# CY8C5888LTI_LP097 register map
File version: 0.1
Registers are 8-bit, read-write, no defined reset value unless marked. A register's access mark holds for its fields unless they carry their own. Offsets are from the block's base; [hi:lo] are bit positions; 'fields as' and 'values as' point back to an identical list.

## PIXY2UARTReset
Base 0x00000000
0x40006478 PIXY2UARTReset_CONTROL_REG

## PIXY2PacketCount
Base 0x00000000
0x4000640D PIXY2PacketCount_COUNTER — UDB.A0 - Current Counter Value
0x4000642D PIXY2PacketCount_PERIOD — UDB.D0 - Assigned Period
0x4000643D PIXY2PacketCount_COMPARE — UDB.D1 - Assigned Compare Value
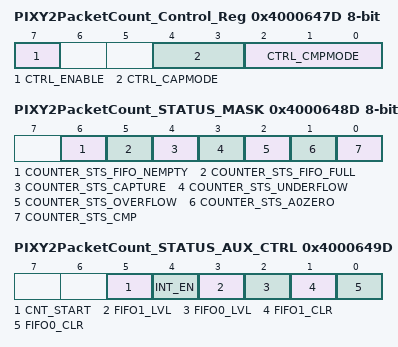
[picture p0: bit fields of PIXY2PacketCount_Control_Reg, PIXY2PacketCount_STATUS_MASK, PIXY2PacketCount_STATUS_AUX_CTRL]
0x4000647D PIXY2PacketCount_Control_Reg — UDB Control Register - Assigned Control Register Value
  [7] CTRL_ENABLE — Enable Counter
  [4:3] CTRL_CAPMODE — Capture mode
  [2:0] CTRL_CMPMODE — Compare mode
0x4000648D PIXY2PacketCount_STATUS_MASK — UDB Status bits Interrupt Mask Enable Register
  [6] COUNTER_STS_FIFO_NEMPTY — FIFO Not Empty Status
  [5] COUNTER_STS_FIFO_FULL — FIFO Full Status
  [4] COUNTER_STS_CAPTURE — Capture Status
  [3] COUNTER_STS_UNDERFLOW — Underflow status
  [2] COUNTER_STS_OVERFLOW — Overflow status
  [1] COUNTER_STS_A0ZERO — A0 Zero ouput status
  [0] COUNTER_STS_CMP — Compare output status
0x4000649D PIXY2PacketCount_STATUS_AUX_CTRL — UDB Auxilliary Control Register
  [5] CNT_START — FIFO0 clear
    0=E_CNT_START0 (Disable counter); 1=E_CNT_START1 (Enable counter)
  [4] INT_EN
    0=E_INT_EN0 (Interrupt disabled); 1=E_INT_EN1 (Interrupt enabled)
  [3] FIFO1_LVL — FIFO level
    0=E_FIFO_LVL_0 (FIFO LVL: input mode: FIFO not full; output mode: FIFO not empty); 1=E_FIFO_LVL_1 (FIFO LVL: input mode: FIFO at least 1/2 empty; output mode: FIFO at least 1/2 full)
  [2] FIFO0_LVL — FIFO level
    values as FIFO1_LVL
  [1] FIFO1_CLR — FIFO1 clear
    0=E_FIFO_CLR_0 (Normal FIFO operation); 1=E_FIFO_CLR_1 (Clear FIFO state)
  [0] FIFO0_CLR — FIFO0 clear
    values as FIFO1_CLR

## PIXYCountReset
Base 0x00000000
0x4000647E PIXYCountReset_CONTROL_REG

## UARTReset
Base 0x00000000
0x4000657B UARTReset_CONTROL_REG

## LEDDrive
Base 0x00000000
0x4000647C LEDDrive_CONTROL_REG

## LabVIEW_UART — UART
Base 0x00000000
0x4000644E TX_LabVIEW_UART_TX_DATA — TX Data Register
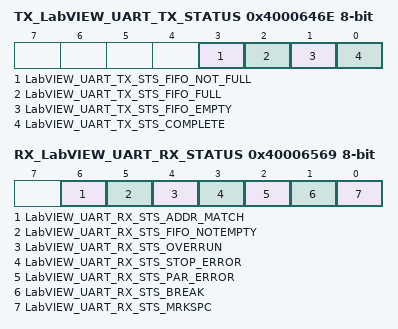
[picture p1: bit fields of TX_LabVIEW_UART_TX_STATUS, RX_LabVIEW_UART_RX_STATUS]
0x4000646E TX_LabVIEW_UART_TX_STATUS — TX status register
  [3] LabVIEW_UART_TX_STS_FIFO_NOT_FULL ro, [2] LabVIEW_UART_TX_STS_FIFO_FULL ro, [1] LabVIEW_UART_TX_STS_FIFO_EMPTY ro, [0] LabVIEW_UART_TX_STS_COMPLETE ro
0x4000652B RX_LabVIEW_UART_RX_ADDRESS1 — RX Address1 Register
0x4000653B RX_LabVIEW_UART_RX_ADDRESS2 — RX Address2 Register
0x4000654B RX_LabVIEW_UART_RX_DATA — RX Data Register
0x40006569 RX_LabVIEW_UART_RX_STATUS — RX status register
  [6] LabVIEW_UART_RX_STS_ADDR_MATCH ro, [5] LabVIEW_UART_RX_STS_FIFO_NOTEMPTY ro, [4] LabVIEW_UART_RX_STS_OVERRUN ro, [3] LabVIEW_UART_RX_STS_STOP_ERROR ro, [2] LabVIEW_UART_RX_STS_PAR_ERROR ro, [1] LabVIEW_UART_RX_STS_BREAK ro, [0] LabVIEW_UART_RX_STS_MRKSPC ro

## ByteCountReset
Base 0x00000000
0x40006579 ByteCountReset_CONTROL_REG

## PIXY2UART — UART
Base 0x00000000
0x40006428 RX_PIXY2UART_RX_ADDRESS1 — RX Address1 Register
0x40006438 RX_PIXY2UART_RX_ADDRESS2 — RX Address2 Register
0x40006448 RX_PIXY2UART_RX_DATA — RX Data Register
0x4000644C TX_PIXY2UART_TX_DATA — TX Data Register
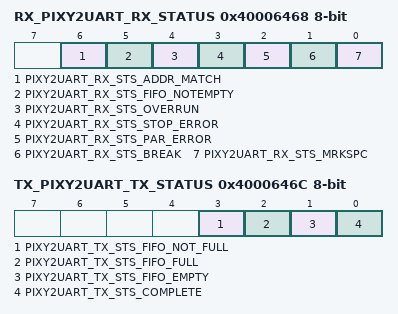
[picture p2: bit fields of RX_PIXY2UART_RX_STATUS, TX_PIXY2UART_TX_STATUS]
0x40006468 RX_PIXY2UART_RX_STATUS — RX status register
  [6] PIXY2UART_RX_STS_ADDR_MATCH ro, [5] PIXY2UART_RX_STS_FIFO_NOTEMPTY ro, [4] PIXY2UART_RX_STS_OVERRUN ro, [3] PIXY2UART_RX_STS_STOP_ERROR ro, [2] PIXY2UART_RX_STS_PAR_ERROR ro, [1] PIXY2UART_RX_STS_BREAK ro, [0] PIXY2UART_RX_STS_MRKSPC ro
0x4000646C TX_PIXY2UART_TX_STATUS — TX status register
  [3] PIXY2UART_TX_STS_FIFO_NOT_FULL ro, [2] PIXY2UART_TX_STS_FIFO_FULL ro, [1] PIXY2UART_TX_STS_FIFO_EMPTY ro, [0] PIXY2UART_TX_STS_COMPLETE ro

## ByteCounter
Base 0x00000000
0x40006409 ByteCounter_COUNTER — UDB.A0 - Current Counter Value
0x40006429 ByteCounter_PERIOD — UDB.D0 - Assigned Period
0x40006439 ByteCounter_COMPARE — UDB.D1 - Assigned Compare Value
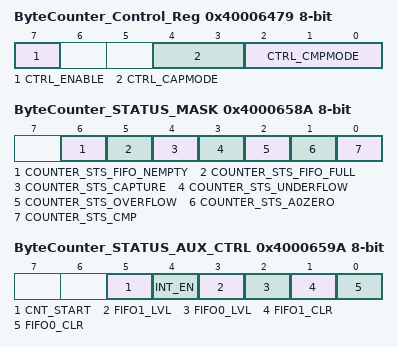
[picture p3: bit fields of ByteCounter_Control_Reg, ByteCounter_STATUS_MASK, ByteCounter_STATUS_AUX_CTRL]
0x40006479 ByteCounter_Control_Reg — UDB Control Register - Assigned Control Register Value
  [7] CTRL_ENABLE — Enable Counter
  [4:3] CTRL_CAPMODE — Capture mode
  [2:0] CTRL_CMPMODE — Compare mode
0x4000658A ByteCounter_STATUS_MASK — UDB Status bits Interrupt Mask Enable Register
  [6] COUNTER_STS_FIFO_NEMPTY — FIFO Not Empty Status
  [5] COUNTER_STS_FIFO_FULL — FIFO Full Status
  [4] COUNTER_STS_CAPTURE — Capture Status
  [3] COUNTER_STS_UNDERFLOW — Underflow status
  [2] COUNTER_STS_OVERFLOW — Overflow status
  [1] COUNTER_STS_A0ZERO — A0 Zero ouput status
  [0] COUNTER_STS_CMP — Compare output status
0x4000659A ByteCounter_STATUS_AUX_CTRL — UDB Auxilliary Control Register
  [5] CNT_START — FIFO0 clear
    0=E_CNT_START0 (Disable counter); 1=E_CNT_START1 (Enable counter)
  [4] INT_EN
    0=E_INT_EN0 (Interrupt disabled); 1=E_INT_EN1 (Interrupt enabled)
  [3] FIFO1_LVL — FIFO level
    0=E_FIFO_LVL_0 (FIFO LVL: input mode: FIFO not full; output mode: FIFO not empty); 1=E_FIFO_LVL_1 (FIFO LVL: input mode: FIFO at least 1/2 empty; output mode: FIFO at least 1/2 full)
  [2] FIFO0_LVL — FIFO level
    values as FIFO1_LVL
  [1] FIFO1_CLR — FIFO1 clear
    0=E_FIFO_CLR_0 (Normal FIFO operation); 1=E_FIFO_CLR_1 (Clear FIFO state)
  [0] FIFO0_CLR — FIFO0 clear
    values as FIFO1_CLR
